# EFM32PG1B register map
File version: 5.8.2
CPU: CM4 r0p1, little endian, MPU, FPU, 3 interrupt priority bits
Registers are 32-bit, read-write, reset 0x0 unless marked. A register's access mark holds for its fields unless they carry their own. Offsets are from the block's base; [hi:lo] are bit positions; {n}, {i} and the like mark numbered series; 'fields as' and 'values as' point back to an identical list.

## GPCRC — General Purpose Cyclic Redundancy Check
Base 0x4001C000
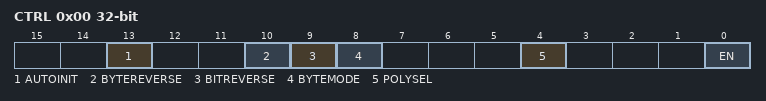
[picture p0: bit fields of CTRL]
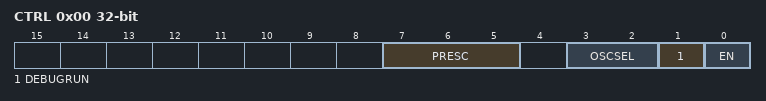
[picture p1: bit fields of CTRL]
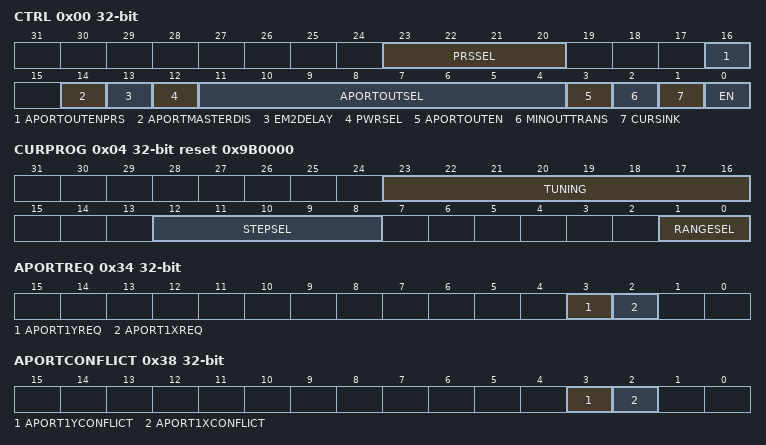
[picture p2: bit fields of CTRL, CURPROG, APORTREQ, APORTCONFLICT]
0x00 CTRL — Control Register
  [13] AUTOINIT — Auto Init Enable
  [10] BYTEREVERSE — Byte Reverse Mode
  [9] BITREVERSE — Byte-level Bit Reverse Enable
  [8] BYTEMODE — Byte Mode Enable
  [4] POLYSEL — Polynomial Select
  [0] EN — CRC Functionality Enable
0x04 CMD wo — Command Register
  [0] INIT — Initialization Enable
0x08 INIT — CRC Init Value
  [31:0] INIT — CRC Initialization Value
0x0C POLY — CRC Polynomial Value
  [15:0] POLY
0x10 INPUTDATA — Input 32-bit Data Register
  [31:0] INPUTDATA — Input Data for 32-bit
0x14 INPUTDATAHWORD — Input 16-bit Data Register
  [15:0] INPUTDATAHWORD — Input Data for 16-bit
0x18 INPUTDATABYTE — Input 8-bit Data Register
  [7:0] INPUTDATABYTE — Input Data for 8-bit
0x1C DATA ro — CRC Data Register
0x20 DATAREV ro — CRC Data Reverse Register
  [31:0] DATAREV — Data Reverse Value
0x24 DATABYTEREV ro — CRC Data Byte Reverse Register
  [31:0] DATABYTEREV — Data Byte Reverse Value

## CRYOTIMER
Base 0x4001E000
0x00 CTRL — Control Register
  [7:5] PRESC — Prescaler Setting
    0=DIV1 (LF Oscillator frequency undivided); 1=DIV2 (LF Oscillator frequency divided by 2); 2=DIV4 (LF Oscillator frequency divided by 4); 3=DIV8 (LF Oscillator frequency divided by 8); 4=DIV16 (LF Oscillator frequency divided by 16); 5=DIV32 (LF Oscillator frequency divided by 32); 6=DIV64 (LF Oscillator frequency divided by 64); 7=DIV128 (LF Oscillator frequency divided by 128)
  [3:2] OSCSEL — Select Low Frequency Oscillator
    0=LFRCO (Select Low Frequency RC Oscillator); 1=LFXO (Select Low Frequency Crystal Oscillator); 2=ULFRCO (Select Ultra Low Frequency RC Oscillator)
  [1] DEBUGRUN — Debug Mode Run Enable
  [0] EN — Enable CRYOTIMER
0x04 PERIODSEL reset 0x20 — Interrupt Duration
  [5:0] PERIODSEL — Interrupts/Wakeup Events Period Setting
0x08 CNT ro — Counter Value
0x0C EM4WUEN — Wake Up Enable
  [0] EM4WU — EM4 Wake-up Enable
0x10 IF ro — Interrupt Flag Register
  [0] PERIOD — Wakeup Event/Interrupt
0x14 IFS wo — Interrupt Flag Set Register
  [0] PERIOD — Set PERIOD Interrupt Flag
0x18 IFC wo — Interrupt Flag Clear Register
  [0] PERIOD — Clear PERIOD Interrupt Flag
0x1C IEN — Interrupt Enable Register
  [0] PERIOD — PERIOD Interrupt Enable

## IDAC0
Base 0x40006000
0x00 CTRL — Control Register
  [23:20] PRSSEL — IDAC Output Enable PRS Channel Select
    {v}=PRSCH{v} (PRS Channel {v} selected.) (v=0..11)
  [16] APORTOUTENPRS — PRS Controlled APORT Output Enable
  [14] APORTMASTERDIS — APORT Bus Master Disable
  [13] EM2DELAY
  [12] PWRSEL — Power Select
  [11:4] APORTOUTSEL — APORT Output Select
    32=APORT1XCH0 (APORT1X Channel 0); 33=APORT1YCH1 (APORT1Y Channel 1); 34=APORT1XCH2 (APORT1X Channel 2); 35=APORT1YCH3 (APORT1Y Channel 3); 36=APORT1XCH4 (APORT1X Channel 4); 37=APORT1YCH5 (APORT1Y Channel 5); 38=APORT1XCH6 (APORT1X Channel 6); 39=APORT1YCH7 (APORT1Y Channel 7); 40=APORT1XCH8 (APORT1X Channel 8); 41=APORT1YCH9 (APORT1Y Channel 9); 42=APORT1XCH10 (APORT1X Channel 10); 43=APORT1YCH11 (APORT1Y Channel 11); 44=APORT1XCH12 (APORT1X Channel 12); 45=APORT1YCH13 (APORT1Y Channel 13); 46=APORT1XCH14 (APORT1X Channel 14); 47=APORT1YCH15 (APORT1Y Channel 15); 48=APORT1XCH16 (APORT1X Channel 16); 49=APORT1YCH17 (APORT1Y Channel 17); 50=APORT1XCH18 (APORT1X Channel 18); 51=APORT1YCH19 (APORT1Y Channel 19); 52=APORT1XCH20 (APORT1X Channel 20); 53=APORT1YCH21 (APORT1Y Channel 21); 54=APORT1XCH22 (APORT1X Channel 22); 55=APORT1YCH23 (APORT1Y Channel 23); 56=APORT1XCH24 (APORT1X Channel 24); 57=APORT1YCH25 (APORT1Y Channel 25); 58=APORT1XCH26 (APORT1X Channel 26); 59=APORT1YCH27 (APORT1Y Channel 27); 60=APORT1XCH28 (APORT1X Channel 28); 61=APORT1YCH29 (APORT1Y Channel 29); 62=APORT1XCH30 (APORT1X Channel 30); 63=APORT1YCH31 (APORT1Y Channel 31)
  [3] APORTOUTEN — APORT Output Enable
  [2] MINOUTTRANS — Minimum Output Transition Enable
  [1] CURSINK — Current Sink Enable
  [0] EN — Current DAC Enable
0x04 CURPROG reset 0x9B0000 — Current Programming Register
  [23:16] TUNING — Tune the Current to Given Accuracy
  [12:8] STEPSEL — Current Step Size Select
  [1:0] RANGESEL — Current Range Select
    0=RANGE0 (Current range set to 0 - 1.6 uA.); 1=RANGE1 (Current range set to 1.6 - 4.7 uA.); 2=RANGE2 (Current range set to 0.5 - 16 uA.); 3=RANGE3 (Current range set to 2 - 64 uA.)
0x0C DUTYCONFIG — Duty Cycle Configuration Register
  [1] EM2DUTYCYCLEDIS — Duty Cycle Enable
0x18 STATUS ro
  [1] APORTCONFLICT — APORT Conflict Output
0x20 IF ro — Interrupt Flag Register
  [1] APORTCONFLICT — APORT Conflict Interrupt Flag
0x24 IFS wo — Interrupt Flag Set Register
  [1] APORTCONFLICT — Set APORTCONFLICT Interrupt Flag
0x28 IFC wo — Interrupt Flag Clear Register
  [1] APORTCONFLICT — Clear APORTCONFLICT Interrupt Flag
0x2C IEN — Interrupt Enable Register
  [1] APORTCONFLICT — APORTCONFLICT Interrupt Enable
0x34 APORTREQ ro — APORT Request Status Register
  [3] APORT1YREQ — 1 If the Bus Connected to APORT1Y is Requested
  [2] APORT1XREQ — 1 If the APORT Bus Connected to APORT1X is Requested
0x38 APORTCONFLICT ro — APORT Request Status Register
  [3] APORT1YCONFLICT — 1 If the Bus Connected to APORT1Y is in Conflict With Another Peripheral
  [2] APORT1XCONFLICT — 1 If the Bus Connected to APORT1X is in Conflict With Another Peripheral

## WDOG0
Base 0x40052000
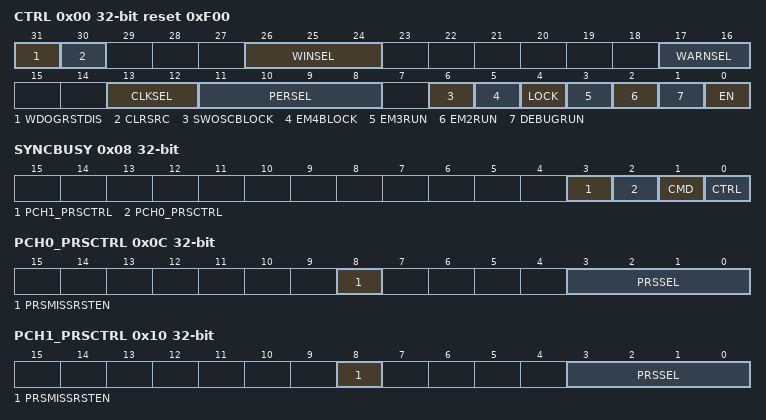
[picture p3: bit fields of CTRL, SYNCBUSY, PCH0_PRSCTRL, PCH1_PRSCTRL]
0x00 CTRL reset 0xF00 — Control Register
  [31] WDOGRSTDIS — Watchdog Reset Disable
  [30] CLRSRC — Watchdog Clear Source
  [26:24] WINSEL — Watchdog Illegal Window Select
  [17:16] WARNSEL — Watchdog Timeout Period Select
  [13:12] CLKSEL — Watchdog Clock Select
    0=ULFRCO; 1=LFRCO; 2=LFXO
  [11:8] PERSEL — Watchdog Timeout Period Select
  [6] SWOSCBLOCK — Software Oscillator Disable Block
  [5] EM4BLOCK — Energy Mode 4 Block
  [4] LOCK — Configuration Lock
  [3] EM3RUN — Energy Mode 3 Run Enable
  [2] EM2RUN — Energy Mode 2 Run Enable
  [1] DEBUGRUN — Debug Mode Run Enable
  [0] EN — Watchdog Timer Enable
0x04 CMD wo — Command Register
  [0] CLEAR — Watchdog Timer Clear
0x08 SYNCBUSY ro — Synchronization Busy Register
  [3] PCH1_PRSCTRL — PCH1_PRSCTRL Register Busy
  [2] PCH0_PRSCTRL — PCH0_PRSCTRL Register Busy
  [1] CMD — CMD Register Busy
  [0] CTRL — CTRL Register Busy
0x0C PCH0_PRSCTRL — PRS Control Register
  [8] PRSMISSRSTEN — PRS Missing Event Will Trigger a Watchdog Reset
  [3:0] PRSSEL — PRS Channel PRS Select
    {v}=PRSCH{v} (PRS Channel {v} selected as input) (v=0..11)
0x10 PCH1_PRSCTRL — PRS Control Register
  fields as PCH0_PRSCTRL
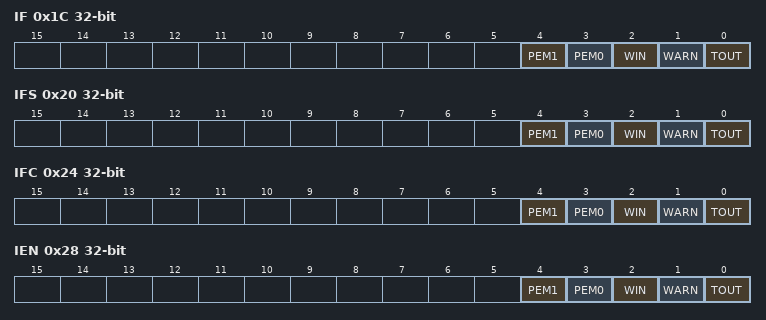
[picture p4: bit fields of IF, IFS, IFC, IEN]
0x1C IF ro — Watchdog Interrupt Flags
  [4] PEM1 — PRS Channel One Event Missing Interrupt Flag
  [3] PEM0 — PRS Channel Zero Event Missing Interrupt Flag
  [2] WIN — WDOG Window Interrupt Flag
  [1] WARN — WDOG Warning Timeout Interrupt Flag
  [0] TOUT — WDOG Timeout Interrupt Flag
0x20 IFS wo — Interrupt Flag Set Register
  [4] PEM1 — Set PEM1 Interrupt Flag
  [3] PEM0 — Set PEM0 Interrupt Flag
  [2] WIN — Set WIN Interrupt Flag
  [1] WARN — Set WARN Interrupt Flag
  [0] TOUT — Set TOUT Interrupt Flag
0x24 IFC wo — Interrupt Flag Clear Register
  [4] PEM1 — Clear PEM1 Interrupt Flag
  [3] PEM0 — Clear PEM0 Interrupt Flag
  [2] WIN — Clear WIN Interrupt Flag
  [1] WARN — Clear WARN Interrupt Flag
  [0] TOUT — Clear TOUT Interrupt Flag
0x28 IEN — Interrupt Enable Register
  [4] PEM1 — PEM1 Interrupt Enable
  [3] PEM0 — PEM0 Interrupt Enable
  [2] WIN — WIN Interrupt Enable
  [1] WARN — WARN Interrupt Enable
  [0] TOUT — TOUT Interrupt Enable

## DI — Device Information
Base 0x0FE081B0
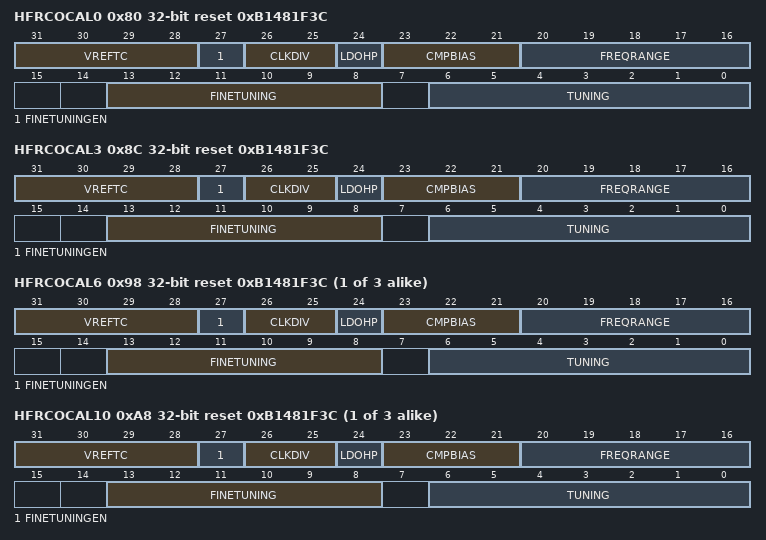
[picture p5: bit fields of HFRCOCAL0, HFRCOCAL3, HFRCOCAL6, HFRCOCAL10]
0x80 HFRCOCAL0 ro reset 0xB1481F3C — HFRCO Calibration Register (4 MHz)
  [31:28] VREFTC rw — HFRCO Temperature Coefficient Trim on Comparator Reference
  [27] FINETUNINGEN rw — Enable Reference for Fine Tuning
  [26:25] CLKDIV rw — Locally Divide HFRCO Clock Output
    0=DIV1 (Divide by 1.); 1=DIV2 (Divide by 2.); 2=DIV4 (Divide by 4.)
  [24] LDOHP rw — HFRCO LDO High Power Mode
  [23:21] CMPBIAS rw — HFRCO Comparator Bias Current
  [20:16] FREQRANGE rw — HFRCO Frequency Range
  [13:8] FINETUNING rw — HFRCO Fine Tuning Value
  [6:0] TUNING rw — HFRCO Tuning Value
0x8C HFRCOCAL3 ro reset 0xB1481F3C — HFRCO Calibration Register (7 MHz)
  fields as HFRCOCAL0
{0x80+4i} HFRCOCAL{i} ro reset 0xB1481F3C (i=6..8) — HFRCO Calibration Register ({3i-5} MHz)
  fields as HFRCOCAL0
{0x80+4i} HFRCOCAL{i} ro reset 0xB1481F3C (i=10..12) — HFRCO Calibration Register ({6i-34} MHz)
  fields as HFRCOCAL0
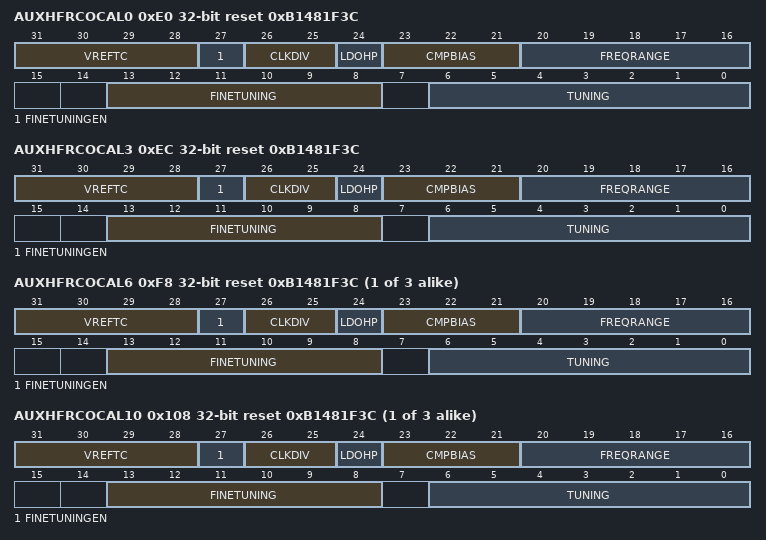
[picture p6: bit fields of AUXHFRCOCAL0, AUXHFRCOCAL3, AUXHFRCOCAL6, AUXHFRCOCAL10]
0xE0 AUXHFRCOCAL0 ro reset 0xB1481F3C — AUXHFRCO Calibration Register (4 MHz)
  fields as HFRCOCAL0
0xEC AUXHFRCOCAL3 ro reset 0xB1481F3C — AUXHFRCO Calibration Register (7 MHz)
  fields as HFRCOCAL0
{0xE0+4i} AUXHFRCOCAL{i} ro reset 0xB1481F3C (i=6..8) — AUXHFRCO Calibration Register ({3i-5} MHz)
  fields as HFRCOCAL0
{0xE0+4i} AUXHFRCOCAL{i} ro reset 0xB1481F3C (i=10..12) — AUXHFRCO Calibration Register ({6i-34} MHz)
  fields as HFRCOCAL0
